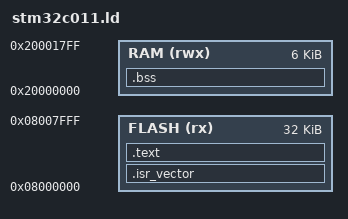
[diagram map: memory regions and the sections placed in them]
ENTRY(Reset_Handler)

MEMORY
{
    FLASH (rx)  : ORIGIN = 0x08000000, LENGTH = 32K
    RAM   (rwx) : ORIGIN = 0x20000000, LENGTH = 6K
}

SECTIONS
{
    .isr_vector :
    {
        . = ALIGN(4);
        KEEP(*(.isr_vector))
        . = ALIGN(4);
    } > FLASH

    .text :
    {
        . = ALIGN(4);
        *(.text*)
        *(.rodata*)
        . = ALIGN(4);
    } > FLASH

    .bss :
    {
        . = ALIGN(4);
        *(.bss*)
        *(COMMON)
        . = ALIGN(4);
    } > RAM
}
